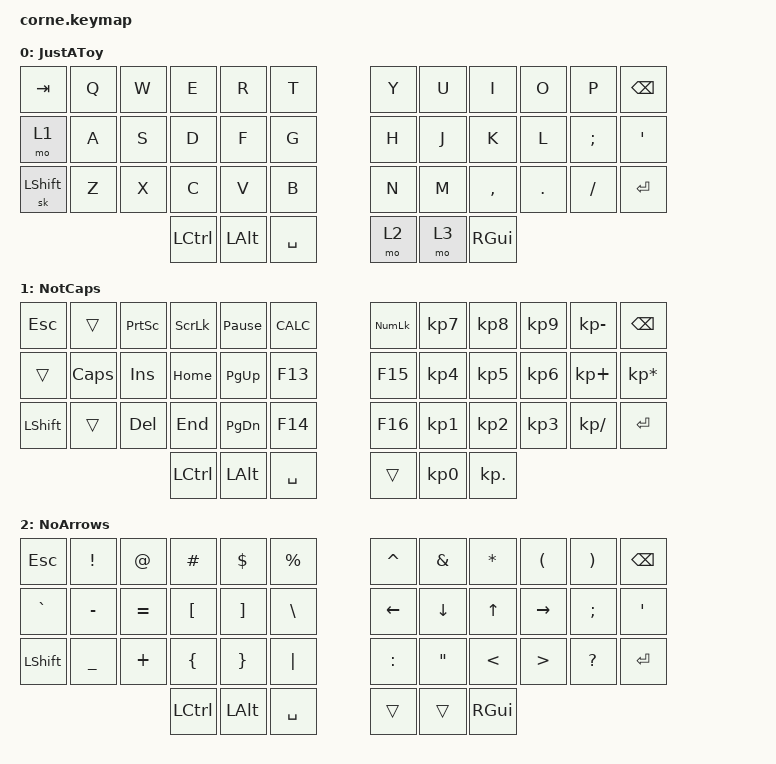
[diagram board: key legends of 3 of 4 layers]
/*
 * Copyright (c) 2020 The ZMK Contributors
 *
 * SPDX-License-Identifier: MIT
 */

#include <behaviors.dtsi>
#include <dt-bindings/zmk/keys.h>
#include <dt-bindings/zmk/bt.h>
#include <dt-bindings/zmk/rgb.h>
#include <dt-bindings/zmk/ext_power.h>
#include <dt-bindings/zmk/outputs.h>

&sl {
    release-after-ms = <500>;
};


/ {
        keymap {
                compatible = "zmk,keymap";

                0_layer {
                label = "JustAToy";                
          
// -----------------------------------------------------------------------------------------
// |  TAB |  Q  |  W  |  E  |  R  |  T  |   |  Y  |  U  |  I  |  O  |  P  | BKSP |
// | MO(1)|  A  |  S  |  D  |  F  |  G  |   |  H  |  J  |  K  |  L  |  ;  |  '   |
// | SSHFT|  Z  |  X  |  C  |  V  |  B  |   |  N  |  M  |  ,  |  .  |  /  | ENTER|
//                    |RCTRL| ALT | SPC |   |MO(2)|MO(3)| GUI |
// -----------------------------------------------------------------------------------------

                        bindings = <
   &kp TAB   &kp Q &kp W &kp E &kp R &kp T      &kp Y &kp U  &kp I     &kp O   &kp P    &kp BSPC
   &mo 1     &kp A &kp S &kp D &kp F &kp G      &kp H &kp J  &kp K     &kp L   &kp SEMI &kp SQT
   &sk LSHFT &kp Z &kp X &kp C &kp V &kp B      &kp N &kp M  &kp COMMA &kp DOT &kp FSLH &kp ENTER
              &kp LCTRL &kp LALT &kp SPACE      &mo 2 &mo 3  &kp RGUI
                        >;
                };
                
                1_layer {
                label = "NotCaps";
                
// -----------------------------------------------------------------------------------------
// |  ESC |     |PSCRN| SLCK|PAUSE| CAL |   | NUM |  7  |  8  |  9  |  -  | BKSP |
// |      | CAPS| INS | HOME|PG_UP| F13 |   | F15 |  4  |  5  |  6  |  +  |   *  |
// | LSHFT|     | DEL | END |PG_DN| F14 |   | F16 |  1  |  2  |  3  |  /  | ENTER|
//                    |RCTRL| ALT | SPC |   |     |  0  |  .  |
// -----------------------------------------------------------------------------------------

                        bindings = <
   &kp ESC    &trans     &kp PSCRN &kp SLCK  &kp PAUSE_BREAK &kp K_CALC &kp KP_NUM &kp KP_N7 &kp KP_N8 &kp KP_N9 &kp KP_MINUS  &kp BSPC
   &trans     &kp CAPS   &kp INS   &kp HOME  &kp PG_UP       &kp F13    &kp F15    &kp KP_N4 &kp KP_N5 &kp KP_N6 &kp KP_PLUS   &kp KP_ASTERISK
   &kp LSHFT  &trans     &kp DEL   &kp END   &kp PG_DN       &kp F14    &kp F16    &kp KP_N1 &kp KP_N2 &kp KP_N3 &kp KP_DIVIDE &kp ENTER
                                   &kp LCTRL &kp LALT        &kp SPACE  &trans     &kp KP_N0 &kp KP_DOT
                        >;
                };
                
                2_layer {
                label = "NoArrows";
                
// -----------------------------------------------------------------------------------------
// |  ESC |  !  |  @  |  #  |  $  |  %  |   |  ^  |  &  |  *  |  (  |  )  | BKSP |
// |   `  |  -  |  =  |  [  |  ]  |  \  |   | LEFT| DOWN|  UP |RIGHT|  ;  |  '   |
// | LSHFT|  _  |  +  |  {  |  }  |  |  |   |  :  |  "  |  <  |  >  |  ?  | ENTER| 
//                    |RCTRL| ALT | SPC |   |     |     | GUI |
// -----------------------------------------------------------------------------------------

                        bindings = <
   &kp  ESC  &kp EXCL  &kp AT    &kp HASH &kp DLLR &kp PRCNT  &kp CARET &kp AMPS &kp STAR &kp LPAR  &kp RPAR  &kp BSPC
   &kp GRAVE &kp MINUS &kp EQUAL &kp LBKT &kp RBKT &kp BSLH   &kp LEFT  &kp DOWN &kp UP   &kp RIGHT &kp SEMI &kp APOS
   &kp LSHFT &kp UNDER &kp PLUS  &kp LBRC &kp RBRC &kp PIPE   &kp COLON &kp DQT  &kp LT   &kp GT    &kp QMARK &kp ENTER
                                   &kp LCTRL &kp LALT &kp SPACE         &trans &trans &kp RGUI
                        >;
                };
                
                3_layer {
                label = "INeedF5";
                
// -----------------------------------------------------------------------------------------
// |  F1  |  F2 |  F3 |  F4 |  F5 |  F6 |   |  F7 |  F8 |  F9 | F10 | F11 | F12 |
// |  F7  |  F8 |  F9 | F10 | F11 | F12 |   |    |USB/BLE|    |     |     |     |
// | LSHFT|     |     |     |     |     |   |BTCLR| BT0 | BT1 | BT2 | BT3 |ENTER| 
//                    |RCTRL| ALT | SPC |   |     |     | GUI |
// -----------------------------------------------------------------------------------------

                        bindings = <
   &kp F1 &kp F2 &kp F3 &kp F4  &kp F5  &kp F6     &kp F7 &kp F8 &kp F9 &kp F10 &kp F11 &kp F12
   &kp F7 &kp F8 &kp F9 &kp F10 &kp F11 &kp F12    &trans &out OUT_TOG &trans &trans &trans
   &kp LSHFT &trans &trans &trans &trans &ext_power EP_TOG    &bt BT_CLR &bt BT_SEL 0 &bt BT_SEL 1 &bt BT_SEL 2 &bt BT_SEL 3 &kp ENTER
                    &kp LCTRL &kp LALT &kp SPACE   &trans &trans &kp RGUI
                        >;
                };
                
        };
};
